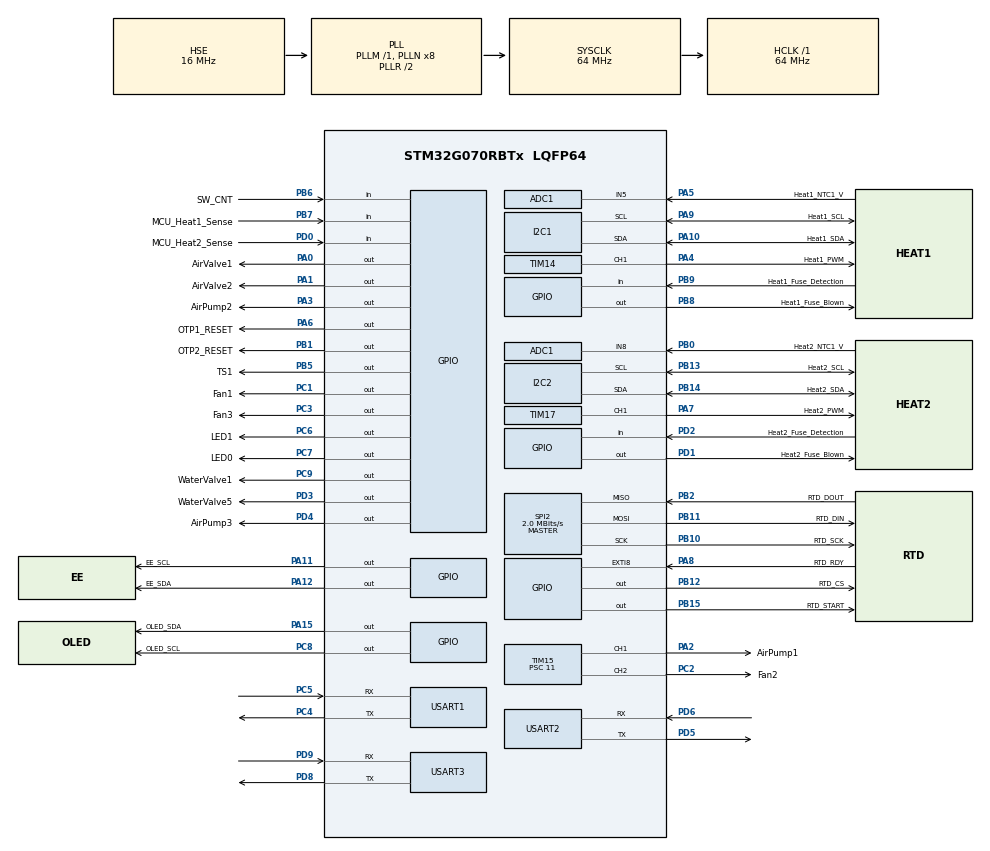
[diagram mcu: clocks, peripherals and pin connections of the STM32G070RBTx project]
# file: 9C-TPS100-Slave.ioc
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ADC1.Channel-0\#ChannelRegularConversion=ADC_CHANNEL_5
ADC1.NbrOfConversionFlag=1
ADC1.Rank-0\#ChannelRegularConversion=1
ADC1.SamplingTime-0\#ChannelRegularConversion=ADC_SAMPLINGTIME_COMMON_1
ADC1.SelectedChannel=ADC_CHANNEL_5|ADC_CHANNEL_8
ADC1.master=1
Dma.Request0=USART2_RX
Dma.Request1=USART2_TX
Dma.Request2=USART1_RX
Dma.Request3=USART1_TX
Dma.Request4=USART3_RX
Dma.Request5=USART3_TX
Dma.USART1_RX.2.Direction=DMA_PERIPH_TO_MEMORY
Dma.USART1_RX.2.EventEnable=DISABLE
Dma.USART1_RX.2.Instance=DMA1_Channel5
Dma.USART1_RX.2.MemDataAlignment=DMA_MDATAALIGN_BYTE
Dma.USART1_RX.2.MemInc=DMA_MINC_ENABLE
Dma.USART1_RX.2.Mode=DMA_CIRCULAR
Dma.USART1_RX.2.PeriphDataAlignment=DMA_PDATAALIGN_BYTE
Dma.USART1_RX.2.PeriphInc=DMA_PINC_DISABLE
Dma.USART1_RX.2.Polarity=HAL_DMAMUX_REQ_GEN_RISING
Dma.USART1_RX.2.Priority=DMA_PRIORITY_LOW
Dma.USART1_RX.2.RequestNumber=1
Dma.USART1_RX.2.SignalID=NONE
Dma.USART1_RX.2.SyncEnable=DISABLE
Dma.USART1_RX.2.SyncPolarity=HAL_DMAMUX_SYNC_NO_EVENT
Dma.USART1_RX.2.SyncRequestNumber=1
Dma.USART1_RX.2.SyncSignalID=NONE
Dma.USART1_TX.3.Direction=DMA_MEMORY_TO_PERIPH
Dma.USART1_TX.3.EventEnable=DISABLE
Dma.USART1_TX.3.Instance=DMA1_Channel6
Dma.USART1_TX.3.MemDataAlignment=DMA_MDATAALIGN_BYTE
Dma.USART1_TX.3.MemInc=DMA_MINC_ENABLE
Dma.USART1_TX.3.Mode=DMA_NORMAL
Dma.USART1_TX.3.PeriphDataAlignment=DMA_PDATAALIGN_BYTE
Dma.USART1_TX.3.PeriphInc=DMA_PINC_DISABLE
Dma.USART1_TX.3.Polarity=HAL_DMAMUX_REQ_GEN_RISING
Dma.USART1_TX.3.Priority=DMA_PRIORITY_LOW
Dma.USART1_TX.3.RequestNumber=1
Dma.USART1_TX.3.SignalID=NONE
Dma.USART1_TX.3.SyncEnable=DISABLE
Dma.USART1_TX.3.SyncPolarity=HAL_DMAMUX_SYNC_NO_EVENT
Dma.USART1_TX.3.SyncRequestNumber=1
Dma.USART1_TX.3.SyncSignalID=NONE
Dma.USART2_RX.0.Direction=DMA_PERIPH_TO_MEMORY
Dma.USART2_RX.0.EventEnable=DISABLE
Dma.USART2_RX.0.Instance=DMA1_Channel1
Dma.USART2_RX.0.MemDataAlignment=DMA_MDATAALIGN_BYTE
Dma.USART2_RX.0.MemInc=DMA_MINC_ENABLE
Dma.USART2_RX.0.Mode=DMA_CIRCULAR
Dma.USART2_RX.0.PeriphDataAlignment=DMA_PDATAALIGN_BYTE
Dma.USART2_RX.0.PeriphInc=DMA_PINC_DISABLE
Dma.USART2_RX.0.Polarity=HAL_DMAMUX_REQ_GEN_RISING
Dma.USART2_RX.0.Priority=DMA_PRIORITY_LOW
Dma.USART2_RX.0.RequestNumber=1
Dma.USART2_RX.0.SignalID=NONE
Dma.USART2_RX.0.SyncEnable=DISABLE
Dma.USART2_RX.0.SyncPolarity=HAL_DMAMUX_SYNC_NO_EVENT
Dma.USART2_RX.0.SyncRequestNumber=1
Dma.USART2_RX.0.SyncSignalID=NONE
Dma.USART2_TX.1.Direction=DMA_MEMORY_TO_PERIPH
Dma.USART2_TX.1.EventEnable=DISABLE
Dma.USART2_TX.1.Instance=DMA1_Channel2
Dma.USART2_TX.1.MemDataAlignment=DMA_MDATAALIGN_BYTE
Dma.USART2_TX.1.MemInc=DMA_MINC_ENABLE
Dma.USART2_TX.1.Mode=DMA_NORMAL
Dma.USART2_TX.1.PeriphDataAlignment=DMA_PDATAALIGN_BYTE
Dma.USART2_TX.1.PeriphInc=DMA_PINC_DISABLE
Dma.USART2_TX.1.Polarity=HAL_DMAMUX_REQ_GEN_RISING
Dma.USART2_TX.1.Priority=DMA_PRIORITY_LOW
Dma.USART2_TX.1.RequestNumber=1
Dma.USART2_TX.1.SignalID=NONE
Dma.USART2_TX.1.SyncEnable=DISABLE
Dma.USART2_TX.1.SyncPolarity=HAL_DMAMUX_SYNC_NO_EVENT
Dma.USART2_TX.1.SyncRequestNumber=1
Dma.USART2_TX.1.SyncSignalID=NONE
Dma.USART3_RX.4.Direction=DMA_PERIPH_TO_MEMORY
Dma.USART3_RX.4.EventEnable=DISABLE
Dma.USART3_RX.4.Instance=DMA1_Channel3
Dma.USART3_RX.4.MemDataAlignment=DMA_MDATAALIGN_BYTE
Dma.USART3_RX.4.MemInc=DMA_MINC_ENABLE
Dma.USART3_RX.4.Mode=DMA_CIRCULAR
Dma.USART3_RX.4.PeriphDataAlignment=DMA_PDATAALIGN_BYTE
Dma.USART3_RX.4.PeriphInc=DMA_PINC_DISABLE
Dma.USART3_RX.4.Polarity=HAL_DMAMUX_REQ_GEN_RISING
Dma.USART3_RX.4.Priority=DMA_PRIORITY_LOW
Dma.USART3_RX.4.RequestNumber=1
Dma.USART3_RX.4.SignalID=NONE
Dma.USART3_RX.4.SyncEnable=DISABLE
Dma.USART3_RX.4.SyncPolarity=HAL_DMAMUX_SYNC_NO_EVENT
Dma.USART3_RX.4.SyncRequestNumber=1
Dma.USART3_RX.4.SyncSignalID=NONE
Dma.USART3_TX.5.Direction=DMA_MEMORY_TO_PERIPH
Dma.USART3_TX.5.EventEnable=DISABLE
Dma.USART3_TX.5.Instance=DMA1_Channel4
Dma.USART3_TX.5.MemDataAlignment=DMA_MDATAALIGN_BYTE
Dma.USART3_TX.5.MemInc=DMA_MINC_ENABLE
Dma.USART3_TX.5.Mode=DMA_NORMAL
Dma.USART3_TX.5.PeriphDataAlignment=DMA_PDATAALIGN_BYTE
Dma.USART3_TX.5.PeriphInc=DMA_PINC_DISABLE
Dma.USART3_TX.5.Polarity=HAL_DMAMUX_REQ_GEN_RISING
Dma.USART3_TX.5.Priority=DMA_PRIORITY_LOW
Dma.USART3_TX.5.RequestNumber=1
Dma.USART3_TX.5.SignalID=NONE
Dma.USART3_TX.5.SyncEnable=DISABLE
Dma.USART3_TX.5.SyncPolarity=HAL_DMAMUX_SYNC_NO_EVENT
Dma.USART3_TX.5.SyncRequestNumber=1
Dma.USART3_TX.5.SyncSignalID=NONE
FREERTOS.Tasks01=defaultTask,0,128,StartDefaultTask,Default,NULL,Dynamic,NULL,NULL
FREERTOS.configTIMER_TASK_PRIORITY=6
FREERTOS.configTOTAL_HEAP_SIZE=30000
FREERTOS.configUSE_TIMERS=1
I2C1.Timing=0x10B17DB5
I2C2.Timing=0x10B17DB5
Mcu.Family=STM32G0
Mcu.Name=STM32G070RBTx
Mcu.Package=LQFP64
NVIC.DMA1_Ch4_7_DMAMUX1_OVR_IRQn=true\:3\:0\:false\:false\:true\:true\:false\:true\:true
NVIC.DMA1_Channel1_IRQn=true\:3\:0\:false\:false\:true\:true\:false\:true\:true
NVIC.DMA1_Channel2_3_IRQn=true\:3\:0\:false\:false\:true\:true\:false\:true\:true
NVIC.EXTI4_15_IRQn=true\:3\:0\:false\:false\:true\:true\:true\:true\:true
NVIC.TIM6_IRQn=true\:3\:0\:false\:false\:true\:false\:false\:true\:true
NVIC.TimeBase=TIM6_IRQn
NVIC.TimeBaseIP=TIM6
NVIC.USART1_IRQn=true\:3\:0\:false\:false\:true\:true\:true\:true\:true
NVIC.USART2_IRQn=true\:3\:0\:false\:false\:true\:true\:true\:true\:true
NVIC.USART3_4_IRQn=true\:3\:0\:false\:false\:true\:true\:true\:true\:true
PA0.GPIO_Label=AirValve1
PA0.Signal=GPIO_Output
PA1.GPIO_Label=AirValve2
PA1.Signal=GPIO_Output
PA10.GPIO_Label=Heat1_SDA
PA10.Mode=I2C
PA10.Signal=I2C1_SDA
PA11\ [PA9].GPIO_Label=EE_SCL
PA11\ [PA9].Signal=GPIO_Output
PA12\ [PA10].GPIO_Label=EE_SDA
PA12\ [PA10].Signal=GPIO_Output
PA13.Mode=Serial_Wire
PA13.Signal=SYS_SWDIO
PA14-BOOT0.Mode=Serial_Wire
PA14-BOOT0.Signal=SYS_SWCLK
PA15.GPIO_Label=OLED_SDA
PA15.GPIO_ModeDefaultOutputPP=GPIO_MODE_OUTPUT_OD
PA15.GPIO_PuPd=GPIO_PULLUP
PA15.GPIO_Speed=GPIO_SPEED_FREQ_HIGH
PA15.PinState=GPIO_PIN_SET
PA15.Signal=GPIO_Output
PA2.GPIO_Label=AirPump1
PA2.Signal=S_TIM15_CH1
PA3.GPIO_Label=AirPump2
PA3.GPIO_PuPd=GPIO_PULLUP
PA3.Signal=GPIO_Output
PA4.GPIO_Label=Heat1_PWM
PA4.Signal=S_TIM14_CH1
PA5.GPIO_Label=Heat1_NTC1_V
PA5.Mode=IN5
PA5.Signal=ADC1_IN5
PA6.GPIO_Label=OTP1_RESET
PA6.GPIO_ModeDefaultOutputPP=GPIO_MODE_OUTPUT_PP
PA6.GPIO_PuPd=GPIO_NOPULL
PA6.PinState=GPIO_PIN_RESET
PA6.Signal=GPIO_Output
PA7.GPIO_Label=Heat2_PWM
PA7.Signal=S_TIM17_CH1
PA8.GPIO_Label=RTD_RDY
PA8.GPIO_ModeDefaultEXTI=GPIO_MODE_IT_FALLING
PA8.Signal=GPXTI8
PA9.GPIO_Label=Heat1_SCL
PA9.Mode=I2C
PA9.Signal=I2C1_SCL
PB0.GPIO_Label=Heat2_NTC1_V
PB0.Mode=IN8
PB0.Signal=ADC1_IN8
PB1.GPIO_Label=OTP2_RESET
PB1.GPIO_PuPd=GPIO_PULLUP
PB1.Signal=GPIO_Output
PB10.GPIO_Label=RTD_SCK
PB10.Mode=Full_Duplex_Master
PB10.Signal=SPI2_SCK
PB11.GPIO_Label=RTD_DIN
PB11.Mode=Full_Duplex_Master
PB11.Signal=SPI2_MOSI
PB12.GPIO_Label=RTD_CS
PB12.Signal=GPIO_Output
PB13.GPIO_Label=Heat2_SCL
PB13.Mode=I2C
PB13.Signal=I2C2_SCL
PB14.GPIO_Label=Heat2_SDA
PB14.Mode=I2C
PB14.Signal=I2C2_SDA
PB15.GPIO_Label=RTD_START
PB15.Signal=GPIO_Output
PB2.GPIO_Label=RTD_DOUT
PB2.Mode=Full_Duplex_Master
PB2.Signal=SPI2_MISO
PB3.Signal=S_TIM1_CH2
PB4.Signal=S_TIM3_CH1
PB5.GPIO_Label=TS1
PB5.GPIO_Speed=GPIO_SPEED_FREQ_VERY_HIGH
PB5.Signal=GPIO_Output
PB6.GPIO_Label=SW_CNT
PB6.Signal=GPIO_Input
PB7.GPIO_Label=MCU_Heat1_Sense
PB7.GPIO_PuPd=GPIO_NOPULL
PB7.Signal=GPIO_Input
PB8.GPIO_Label=Heat1_Fuse_Blown
PB8.GPIO_PuPd=GPIO_NOPULL
PB8.Signal=GPIO_Output
PB9.GPIO_Label=Heat1_Fuse_Detection
PB9.GPIO_PuPd=GPIO_NOPULL
PB9.Signal=GPIO_Input
PC1.GPIO_Label=Fan1
PC1.Signal=GPIO_Output
PC14-OSC32_IN\ (PC14).Mode=LSE-External-Oscillator
PC14-OSC32_IN\ (PC14).Signal=RCC_OSC32_IN
PC15-OSC32_OUT\ (PC15).Mode=LSE-External-Oscillator
PC15-OSC32_OUT\ (PC15).Signal=RCC_OSC32_OUT
PC2.GPIO_Label=Fan2
PC2.Signal=S_TIM15_CH2
PC3.GPIO_Label=Fan3
PC3.Signal=GPIO_Output
PC4.Mode=Asynchronous
PC4.Signal=USART1_TX
PC5.Mode=Asynchronous
PC5.Signal=USART1_RX
PC6.GPIO_Label=LED1
PC6.Signal=GPIO_Output
PC7.GPIO_Label=LED0
PC7.Signal=GPIO_Output
PC8.GPIO_Label=OLED_SCL
PC8.GPIO_ModeDefaultOutputPP=GPIO_MODE_OUTPUT_OD
PC8.GPIO_PuPd=GPIO_PULLUP
PC8.GPIO_Speed=GPIO_SPEED_FREQ_HIGH
PC8.PinState=GPIO_PIN_SET
PC8.Signal=GPIO_Output
PC9.GPIO_Label=WaterValve1
PC9.Signal=GPIO_Output
PD0.GPIO_Label=MCU_Heat2_Sense
PD0.GPIO_PuPd=GPIO_NOPULL
PD0.Signal=GPIO_Input
PD1.GPIO_Label=Heat2_Fuse_Blown
PD1.GPIO_PuPd=GPIO_NOPULL
PD1.Signal=GPIO_Output
PD2.GPIO_Label=Heat2_Fuse_Detection
PD2.GPIO_PuPd=GPIO_NOPULL
PD2.Signal=GPIO_Input
PD3.GPIO_Label=WaterValve5
PD3.Signal=GPIO_Output
PD4.GPIO_Label=AirPump3
PD4.Signal=GPIO_Output
PD5.Mode=Asynchronous
PD5.Signal=USART2_TX
PD6.Mode=Asynchronous
PD6.Signal=USART2_RX
PD8.Mode=Asynchronous
PD8.Signal=USART3_TX
PD9.Mode=Asynchronous
PD9.Signal=USART3_RX
PF0-OSC_IN\ (PF0).Mode=HSE-External-Oscillator
PF0-OSC_IN\ (PF0).Signal=RCC_OSC_IN
PF1-OSC_OUT\ (PF1).Mode=HSE-External-Oscillator
PF1-OSC_OUT\ (PF1).Signal=RCC_OSC_OUT
ProjectManager.HeapSize=0x200
ProjectManager.StackSize=0x400
ProjectManager.TargetToolchain=CMake
RCC.ADCFreq_Value=64000000
RCC.AHBFreq_Value=64000000
RCC.CortexFreq_Value=64000000
RCC.EXTERNAL_CLOCK_VALUE=48000
RCC.HCLKFreq_Value=64000000
RCC.HSE_VALUE=16000000
RCC.HSI_VALUE=16000000
RCC.PLLSourceVirtual=RCC_PLLSOURCE_HSE
RCC.SYSCLKFreq_VALUE=64000000
RCC.SYSCLKSource=RCC_SYSCLKSOURCE_PLLCLK
RCC.VCOOutputFreq_Value=128000000
SH.S_TIM14_CH1.0=TIM14_CH1,PWM Generation1 CH1
SH.S_TIM15_CH1.0=TIM15_CH1,PWM Generation1 CH1
SH.S_TIM15_CH2.0=TIM15_CH2,PWM Generation2 CH2
SH.S_TIM17_CH1.0=TIM17_CH1,PWM Generation1 CH1
SH.S_TIM1_CH2.0=TIM1_CH2
SH.S_TIM3_CH1.0=TIM3_CH1
SPI2.BaudRatePrescaler=SPI_BAUDRATEPRESCALER_32
SPI2.CLKPhase=SPI_PHASE_2EDGE
SPI2.CalculateBaudRate=2.0 MBits/s
SPI2.DataSize=SPI_DATASIZE_8BIT
SPI2.Direction=SPI_DIRECTION_2LINES
SPI2.Mode=SPI_MODE_MASTER
SPI2.VirtualType=VM_MASTER
TIM14.Channel=TIM_CHANNEL_1
TIM14.Period=1999
TIM14.Prescaler=31
TIM15.Channel-PWM\ Generation1\ CH1=TIM_CHANNEL_1
TIM15.Channel-PWM\ Generation2\ CH2=TIM_CHANNEL_2
TIM15.Period=255
TIM15.Prescaler=11
TIM17.Channel=TIM_CHANNEL_1
TIM17.Period=1999
TIM17.Prescaler=31
TIM7.Prescaler=63
USART1.VirtualMode-Asynchronous=VM_ASYNC
USART2.VirtualMode-Asynchronous=VM_ASYNC
USART3.VirtualMode-Asynchronous=VM_ASYNC
VP_FREERTOS_VS_CMSIS_V1.Mode=CMSIS_V1
VP_SYS_VS_tim6.Mode=TIM6
VP_TIM14_VS_ClockSourceINT.Mode=Enable_Timer
VP_TIM16_VS_ClockSourceINT.Mode=Enable_Timer
VP_TIM17_VS_ClockSourceINT.Mode=Enable_Timer
VP_TIM7_VS_ClockSourceINT.Mode=Enable_Timer
board=custom

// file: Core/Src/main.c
/* USER CODE BEGIN Header */
/**
  ******************************************************************************
  * @file           : main.c
  * @brief          : Main program body
  ******************************************************************************
  * @attention
  *
  * Copyright (c) 2025 STMicroelectronics.
  * All rights reserved.
  *
  * This software is licensed under terms that can be found in the LICENSE file
  * in the root directory of this software component.
  * If no LICENSE file comes with this software, it is provided AS-IS.
  *
  ******************************************************************************
  */
/* USER CODE END Header */
#include "main.h"
#include "cmsis_os.h"
#include "adc.h"
#include "dma.h"
#include "i2c.h"
#include "spi.h"
#include "tim.h"
#include "usart.h"
#include "gpio.h"

/* USER CODE BEGIN Includes */
#include "Modules/Debug/debug_rtt.h"
#include "Config/product_config.h"
#include "Modules/Log/module_log.h"
/* USER CODE END Includes */

/* USER CODE BEGIN PV */

// extern volatile uint8_t uart_rx_byte;
// extern volatile uint8_t uart_rx_buffer[UART_RX_BUF_SIZE];
/* USER CODE END PV */

void SystemClock_Config(void);
void MX_FREERTOS_Init(void);

int main(void)
{

  /* MCU Configuration--------------------------------------------------------*/

  /* Reset of all peripherals, Initializes the Flash interface and the Systick. */
  HAL_Init();

  /* USER CODE BEGIN Init */
  DebugRtt_Init();
  LOG_I("App %s startup",PRODUCT_FIRMWARE_VERSION_STRING);
  /* USER CODE END Init */

  /* Configure the system clock */
  SystemClock_Config();

  /* Initialize all configured peripherals */
  MX_GPIO_Init();
  MX_DMA_Init();
  MX_ADC1_Init();
  MX_I2C1_Init();
  MX_I2C2_Init();
  MX_SPI2_Init();
  MX_TIM14_Init();
  MX_TIM16_Init();
  MX_TIM17_Init();
  MX_USART1_UART_Init();
  MX_USART2_UART_Init();
  MX_USART3_UART_Init();
  MX_TIM15_Init();
  MX_TIM7_Init();
  /* USER CODE BEGIN 2 */
	//HAL_Delay(100);

  /* USER CODE END 2 */

  /* Call init function for freertos objects (in cmsis_os2.c) */
  MX_FREERTOS_Init();

  /* Start scheduler */
  osKernelStart();

  /* We should never get here as control is now taken by the scheduler */

  /* Infinite loop */
  while (1)
  {

  }
}

void SystemClock_Config(void)
{
  RCC_OscInitTypeDef RCC_OscInitStruct = {0};
  RCC_ClkInitTypeDef RCC_ClkInitStruct = {0};

  /** Configure the main internal regulator output voltage
  */
  HAL_PWREx_ControlVoltageScaling(PWR_REGULATOR_VOLTAGE_SCALE1);

  /** Initializes the RCC Oscillators according to the specified parameters
  * in the RCC_OscInitTypeDef structure.
  */
  RCC_OscInitStruct.OscillatorType = RCC_OSCILLATORTYPE_HSE;
  RCC_OscInitStruct.HSEState = RCC_HSE_ON;
  RCC_OscInitStruct.PLL.PLLState = RCC_PLL_ON;
  RCC_OscInitStruct.PLL.PLLSource = RCC_PLLSOURCE_HSE;
  RCC_OscInitStruct.PLL.PLLM = RCC_PLLM_DIV1;
  RCC_OscInitStruct.PLL.PLLN = 8;
  RCC_OscInitStruct.PLL.PLLP = RCC_PLLP_DIV2;
  RCC_OscInitStruct.PLL.PLLR = RCC_PLLR_DIV2;
  if (HAL_RCC_OscConfig(&RCC_OscInitStruct) != HAL_OK)
  {
    Error_Handler();
  }

  /** Initializes the CPU, AHB and APB buses clocks
  */
  RCC_ClkInitStruct.ClockType = RCC_CLOCKTYPE_HCLK|RCC_CLOCKTYPE_SYSCLK
                              |RCC_CLOCKTYPE_PCLK1;
  RCC_ClkInitStruct.SYSCLKSource = RCC_SYSCLKSOURCE_PLLCLK;
  RCC_ClkInitStruct.AHBCLKDivider = RCC_SYSCLK_DIV1;
  RCC_ClkInitStruct.APB1CLKDivider = RCC_HCLK_DIV1;

  if (HAL_RCC_ClockConfig(&RCC_ClkInitStruct, FLASH_LATENCY_2) != HAL_OK)
  {
    Error_Handler();
  }
}

void HAL_TIM_PeriodElapsedCallback(TIM_HandleTypeDef *htim)
{
  if (htim->Instance == TIM6)
  {
    HAL_IncTick();
  }
}

void Error_Handler(void)
{
  __disable_irq();
  while (1)
  {
  }
}

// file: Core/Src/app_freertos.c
/* USER CODE BEGIN Header */
/**
  ******************************************************************************
  * File Name          : app_freertos.c
  * Description        : Code for freertos applications
  ******************************************************************************
  * @attention
  *
  * Copyright (c) 2025 STMicroelectronics.
  * All rights reserved.
  *
  * This software is licensed under terms that can be found in the LICENSE file
  * in the root directory of this software component.
  * If no LICENSE file comes with this software, it is provided AS-IS.
  *
  ******************************************************************************
  */
/* USER CODE END Header */

#include "FreeRTOS.h"
#include "task.h"
#include "main.h"
#include "cmsis_os.h"

/* USER CODE BEGIN Includes */
#include "App/System/app_main.h"
/* USER CODE END Includes */

osThreadId defaultTaskHandle;

void StartDefaultTask(void const * argument);

void MX_FREERTOS_Init(void); /* (MISRA C 2004 rule 8.1) */

void MX_FREERTOS_Init(void) {

  /* Create the thread(s) */
  /* definition and creation of defaultTask */
  osThreadDef(defaultTask, StartDefaultTask, osPriorityNormal, 0, 128);
  defaultTaskHandle = osThreadCreate(osThread(defaultTask), NULL);

}

void StartDefaultTask(void const * argument)
{
  /* USER CODE BEGIN StartDefaultTask */
  /* Infinite loop */
  for(;;)
  {
    //osDelay(1);
    AppMain_FreeRTOS_Init();
    vTaskDelete(NULL);
  }
  /* USER CODE END StartDefaultTask */
}
